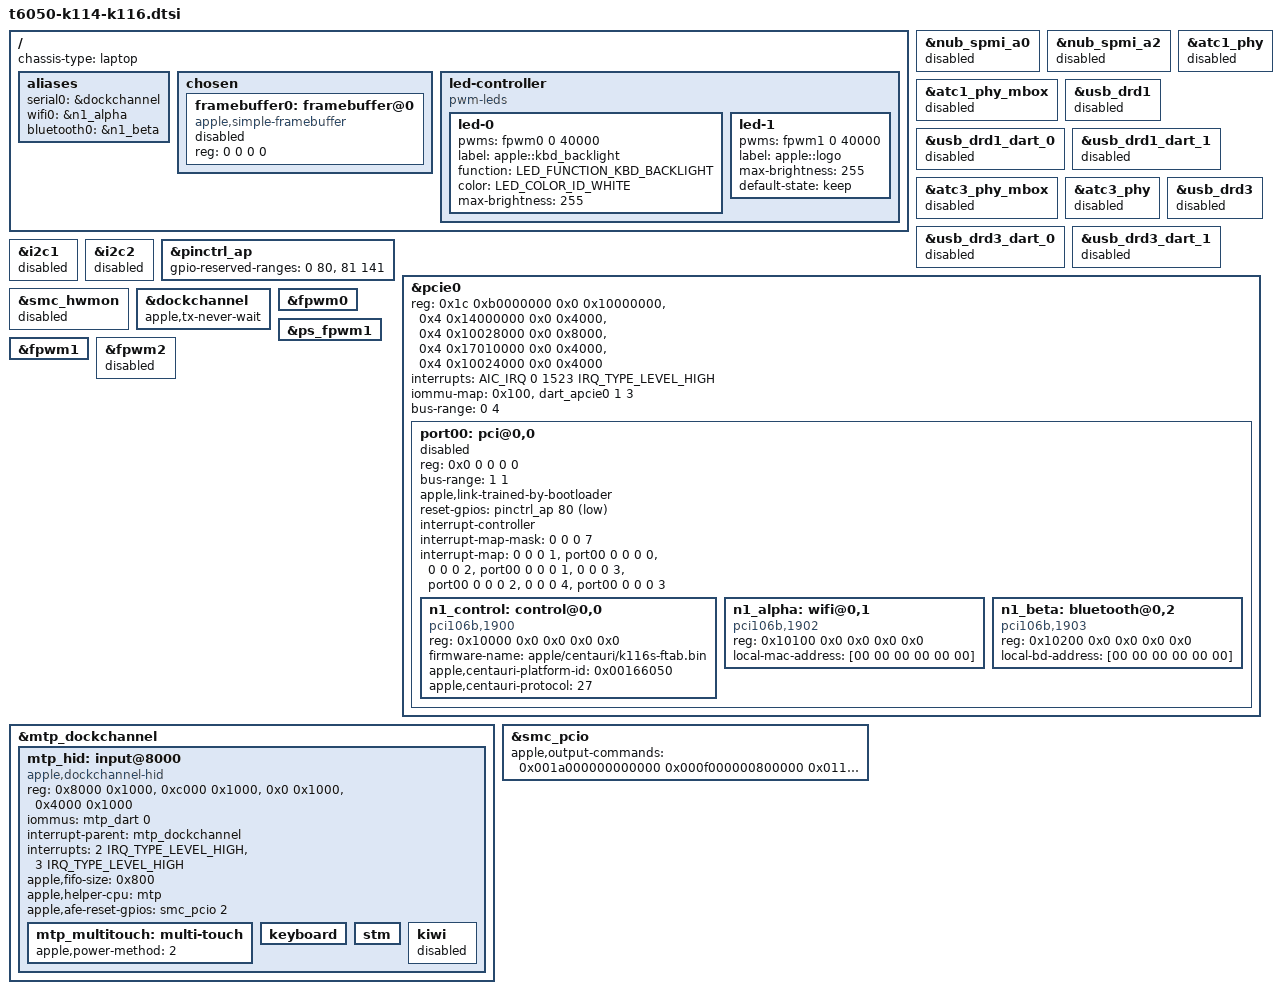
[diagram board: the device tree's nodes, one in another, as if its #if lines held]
// SPDX-License-Identifier: GPL-2.0+ OR MIT
/*
 * MacBook Pro (14-inch and 16-inch PROLED XDR, M5 Pro and M5 Max, 2026)
 *
 * Shared by K114c, K114s, K116c and K116s. These are the J714/J716 MacBook Pros
 * with a tandem OLED panel that takes touch input, and a rear Apple logo that is
 * lit by its own light. Everything here comes from the boards' Apple device tree
 * (ADT) as shipped with macOS 27.2. None of it has been tested on the hardware yet.
 *
 * Against J716c the ADT differs in:
 *  - the panel: no I2C backlight driver (i2c7 disp-bklt) and no dp855 TCON; an
 *    "ixora" TCON and a display NAND on spi4 instead. The OLED needs no separate
 *    backlight controller, so the panel only ever runs through the display
 *    coprocessor here, as the boot framebuffer for now.
 *  - the MTP transport: a "kiwi" interface (the touchscreen) next to the trackpad.
 *  - the FPWM channels: pwm1 (fpwm,s5l8920x at 0x305044000) drives the rear logo
 *    ("bklb-backlight", 25 kHz), and pwm2 (0x305048000, "mesa-backlight", 100 Hz)
 *    exists only on these boards.
 *
 * The M5 Pro boards (K114s, K116s) use the same die and, in the static ADT, the
 * same CPU list as the M5 Max ones; the boot loader drops the cores a part does
 * not have from this tree using the ADT the Mac boots with.
 *
 * Copyright The Asahi Linux Contributors
 */

/dts-v1/;

#include <dt-bindings/leds/common.h>

#include "t6050-max.dtsi"

/ {
	chassis-type = "laptop";

	aliases {
		serial0 = &dockchannel;
#ifdef T6050_K116S
		/* The loader fills the N1's factory addresses through these */
		wifi0 = &n1_alpha;
		bluetooth0 = &n1_beta;
#endif
	};

	chosen {
		#address-cells = <2>;
		#size-cells = <2>;
		ranges;

		framebuffer0: framebuffer@0 {
			compatible = "apple,simple-framebuffer", "simple-framebuffer";
			reg = <0 0 0 0>; /* To be filled by the loader */
			/* Format properties will be added by the loader */
			status = "disabled";
		};
	};

	led-controller {
		compatible = "pwm-leds";

		/* ADT /arm-io/pwm0/kbd-backlight: default-hz 25000 */
		led-0 {
			pwms = <&fpwm0 0 40000>;
			label = "apple::kbd_backlight";
			function = LED_FUNCTION_KBD_BACKLIGHT;
			color = <LED_COLOR_ID_WHITE>;
			max-brightness = <255>;
		};

		/*
		 * The rear Apple logo, ADT /arm-io/pwm1/bklb-backlight: default-hz 25000.
		 * Keep whatever state the boot loader left it in. The ADT's brightness
		 * mapping (nits-to-pwm-percentage, calibrated per device through syscfg
		 * CGBl) is policy for user space, and its use-enable-pulse is not
		 * handled yet.
		 */
		led-1 {
			pwms = <&fpwm1 0 40000>;
			label = "apple::logo";
			max-brightness = <255>;
			default-state = "keep";
		};
	};
};

/* ATC1, ATC3 and the PD controller buses nub-spmi-a0 and -a2: not yet described for these boards */
&nub_spmi_a0 {
	status = "disabled";
};

&nub_spmi_a2 {
	status = "disabled";
};

&atc1_phy_mbox {
	status = "disabled";
};

&atc1_phy {
	status = "disabled";
};

&usb_drd1 {
	status = "disabled";
};

&usb_drd1_dart_0 {
	status = "disabled";
};

&usb_drd1_dart_1 {
	status = "disabled";
};

&atc3_phy_mbox {
	status = "disabled";
};

&atc3_phy {
	status = "disabled";
};

&usb_drd3 {
	status = "disabled";
};

&usb_drd3_dart_0 {
	status = "disabled";
};

&usb_drd3_dart_1 {
	status = "disabled";
};

&i2c1 {
	status = "disabled";
};

&i2c2 {
	status = "disabled";
};

/*
 * As on J716c, where reading pin 112 takes an SError, only the pins a node
 * here names are exposed, and none is yet. The N1 on PCIe port 0 needs its
 * board's platform ID, which the static ADT does not carry, so the port and
 * its PERST# pin stay unused for now.
 */
&pinctrl_ap {
	/* Only PCIe port 0's PERST#, pin 80, is exposed */
	gpio-reserved-ranges = <0 80>, <81 141>;
};

#ifdef T6050_K116S
/*
 * PCIe port 0: the N1 (Wi-Fi and Bluetooth), laid out as on J714s. ADT apcie0
 * gives port 0's registers and IRQ 1523, pci-bridge0's PERST# is GPIO 80, and
 * the N1's three functions are on DART streams 1-3.
 */
&pcie0 {
	reg = <0x1c 0xb0000000 0x0 0x10000000>,
	      <0x4 0x14000000 0x0 0x4000>,
	      <0x4 0x10028000 0x0 0x8000>,
	      <0x4 0x17010000 0x0 0x4000>,
	      <0x4 0x10024000 0x0 0x4000>;
	reg-names = "config", "rc", "port0", "phy0", "intr2axi0";
	interrupts = <AIC_IRQ 0 1523 IRQ_TYPE_LEVEL_HIGH>;
	interrupt-names = "port0";
	iommu-map = <0x100 &dart_apcie0 1 3>;
	bus-range = <0 4>;
	status = "okay";

	port00: pci@0,0 {
		device_type = "pci";
		reg = <0x0 0 0 0 0>;
		bus-range = <1 1>;
		apple,link-trained-by-bootloader;
		/* PERST#: ADT pci-bridge0 function-perst, GPIO 80 */
		reset-gpios = <&pinctrl_ap 80 GPIO_ACTIVE_LOW>;
		status = "disabled";

		#address-cells = <3>;
		#size-cells = <2>;
		ranges;

		interrupt-controller;
		#interrupt-cells = <1>;
		interrupt-map-mask = <0 0 0 7>;
		interrupt-map = <0 0 0 1 &port00 0 0 0 0>,
				<0 0 0 2 &port00 0 0 0 1>,
				<0 0 0 3 &port00 0 0 0 2>,
				<0 0 0 4 &port00 0 0 0 3>;

		/* platform ID (ADT /chosen board-id 0x16 << 16) | chip 0x6050 */
		n1_control: control@0,0 {
			compatible = "pci106b,1900";
			reg = <0x10000 0x0 0x0 0x0 0x0>;
			firmware-name = "apple/centauri/k116s-ftab.bin";
			apple,centauri-platform-id = <0x00166050>;
			apple,centauri-protocol = <27>;
		};

		n1_alpha: wifi@0,1 {
			compatible = "pci106b,1902";
			reg = <0x10100 0x0 0x0 0x0 0x0>;
			local-mac-address = [00 00 00 00 00 00];
		};

		n1_beta: bluetooth@0,2 {
			compatible = "pci106b,1903";
			reg = <0x10200 0x0 0x0 0x0 0x0>;
			local-bd-address = [00 00 00 00 00 00];
		};
	};
};
#else
/*
 * The K114s N1 needs its own platform ID (its ADT /chosen board-id << 16 | 0x6050)
 * before the port can be described. aura's T6050 hand-off still wants the host's
 * iommu-map to mark the ports as it found them, so carry it with the host disabled.
 */
&pcie0 {
	iommu-map = <0x100 &dart_apcie0 1 3>;
	bus-range = <0 4>;
	status = "disabled";
};
#endif

/* These boards' SMC fan and power keys are not yet checked */
&smc_hwmon {
	status = "disabled";
};

/*
 * The console is on the USB debug link, which drains only while a host reads
 * it; the machine also boots with nothing attached there.
 */
&dockchannel {
	apple,tx-never-wait;
	status = "okay";
};

&fpwm0 {
	status = "okay";
};

&ps_fpwm1 {
	status = "okay";
};

&fpwm1 {
	status = "okay";
};

/*
 * ADT /arm-io/pwm2/mesa-backlight (default-hz 100), next to the Touch ID sensor
 * (spi2/mesa). What it lights and how macOS drives it is not known yet.
 */
&fpwm2 {
	status = "disabled";
};

/*
 * The keyboard, trackpad and touchscreen: the HID transport on the MTP's
 * DockChannel FIFO, laid out as on J716c (ADT dockchannel-mtp/mtp-transport).
 */
&mtp_dockchannel {
	mtp_hid: input@8000 {
		compatible = "apple,dockchannel-hid";
		reg = <0x8000 0x1000>, <0xc000 0x1000>,
		      <0x0 0x1000>, <0x4000 0x1000>;
		reg-names = "config", "data", "rmt-config", "rmt-data";
		iommus = <&mtp_dart 0>;
		interrupt-parent = <&mtp_dockchannel>;
		interrupts = <2 IRQ_TYPE_LEVEL_HIGH>,
			     <3 IRQ_TYPE_LEVEL_HIGH>;
		interrupt-names = "tx", "rx";
		apple,fifo-size = <0x800>;
		apple,helper-cpu = <&mtp>;
		/* ADT multi-touch function-afe-reset: pKW8('pcIO', 0x10000, 0x11c0000) */
		apple,afe-reset-gpios = <&smc_pcio 2 GPIO_ACTIVE_HIGH>;

		mtp_multitouch: multi-touch {
			apple,power-method = <2>;
		};

		keyboard {
		};

		stm {
		};

		/*
		 * The touchscreen (ADT mtp-transport/kiwi, image-tag "fsat"). macOS
		 * sends it firmware through the same CBOR bootloader as the trackpad.
		 * Its power, reset, 24 MHz clock and display-sync lines are SoC GPIOs
		 * (nub-gpio0 0x1a, 0x19, 0x16; gpio0 0xb), with an SMC power reference
		 * (pKW4('rCIO', 0x20000)) and the TSRC clock source. How that load and
		 * the report format map onto this transport is still being worked
		 * out, so the interface stays off until it has been tested.
		 */
		kiwi: kiwi {
			status = "disabled";
		};
	};
};

/*
 * The board's pcIO outputs, from the ADT: dp2hdmi_pwr_en pKW8('pcIO', 0, 0x1a0000),
 * hdmi_pwr_en pKW8('pcIO', 0x800000, 0xf0000), and the trackpad AFE reset (2),
 * pKW8('pcIO', 0x10000, 0x11c0000); the same as on J716c.
 */
&smc_pcio {
	apple,output-commands = /bits/ 64 <0x001a000000000000 0x000f000000800000 0x011c000000010000>;
};
